# MCU_ECC_AGGR1_ECC_AGGR register map
Vendor: Texas Instruments
Peripheral module from a debugger description file (folder am65x).
Registers are 32-bit, access not given, reset 0x0 unless marked. A register's access mark holds for its fields unless they carry their own. Offsets are as the file gives them; lines under a group give offsets from that group; [hi:lo] are bit positions; {n}, {i} and the like mark numbered series; 'fields as' and 'values as' point back to an identical list; <NAME> marks a mode.

## MCU_ECC_AGGR1_ECC_AGGR (part 1 of 2)
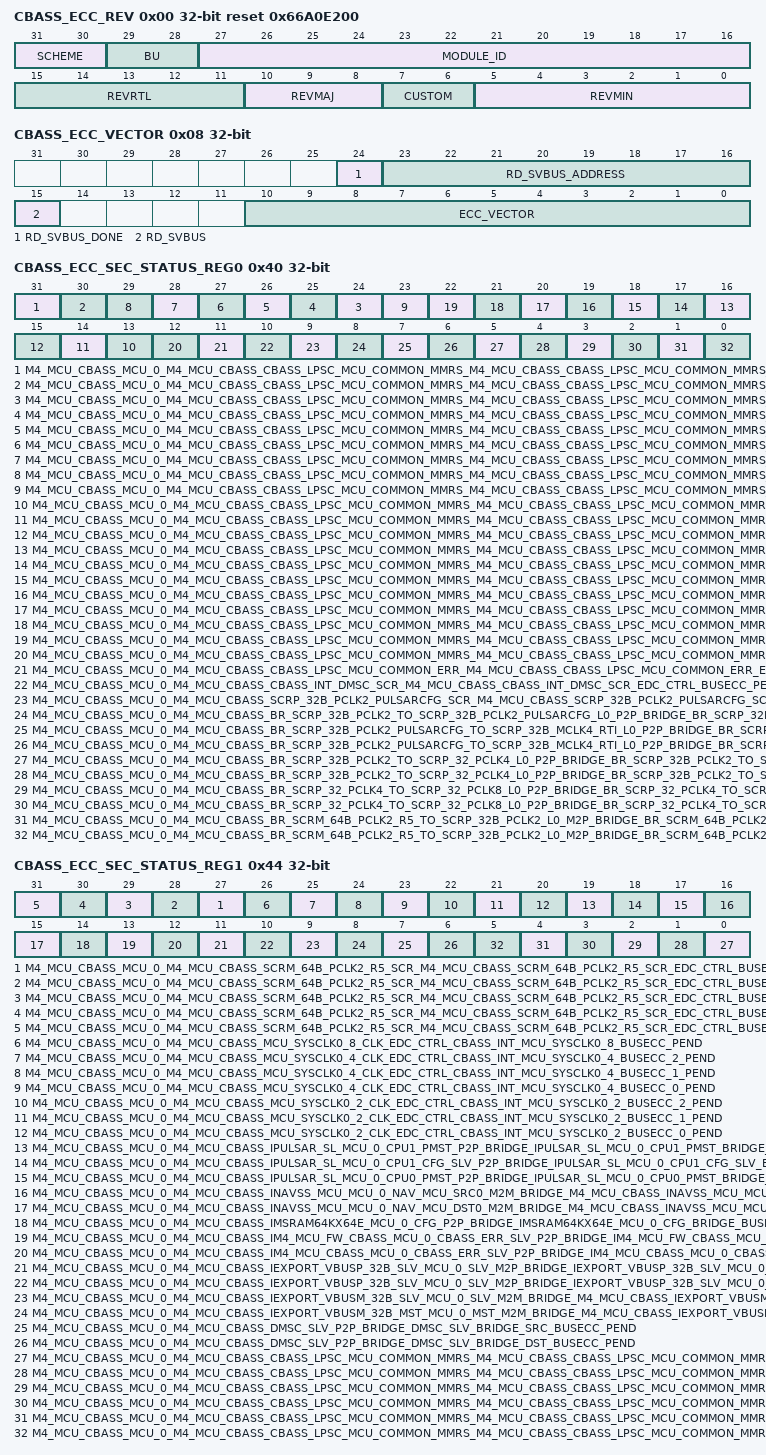
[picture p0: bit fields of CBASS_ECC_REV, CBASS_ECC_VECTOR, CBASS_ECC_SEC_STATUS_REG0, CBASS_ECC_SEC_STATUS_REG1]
0x00 CBASS_ECC_REV ro reset 0x66A0E200 — Return to the . Revision parameters
  [31:30] SCHEME
  [29:28] BU
  [27:16] MODULE_ID
  [15:11] REVRTL — RTL version
  [10:8] REVMAJ — Major version
  [7:6] CUSTOM — Custom version
  [5:0] REVMIN — Minor version
0x08 CBASS_ECC_VECTOR — Return to the . ECC Vector Register
  [24] RD_SVBUS_DONE — Status to indicate if read on serial VBUS is complete, write of any value will clear this bit. (access RW1C)
  [23:16] RD_SVBUS_ADDRESS rw — Read address
  [15] RD_SVBUS — Write 1 to trigger a read on the serial VBUS (access RW1S)
  [10:0] ECC_VECTOR rw — Value written to select the corresponding ECC RAM for control or status
0x0C CBASS_ECC_STAT ro reset 0x57 — Return to the . Misc Status
  [10:0] NUM_RAMS — Indicates the number of RAMS serviced by the ECC aggregator
0x3C CBASS_ECC_SEC_EOI_REG — Return to the . EOI Register
  [0] EOI_WR — EOI Register (access RW1S)
0x40 CBASS_ECC_SEC_STATUS_REG0 — Return to the . Interrupt Status Register 0
  [31] M4_MCU_CBASS_MCU_0_M4_MCU_CBASS_CBASS_LPSC_MCU_COMMON_MMRS_M4_MCU_CBASS_CBASS_LPSC_MCU_COMMON_MMRS_EDC_CTRL_BUSECC_3_PEND — Interrupt Pending Status for m4_mcu_cbass_mcu_0_m4_mcu_cbass_cbass_LPSC_mcu_common_mmrs_m4_mcu_cbass_cbass_LPSC_mcu_common_mmrs_edc_ctrl_busecc_3__pend (access RW1S)
  [30] M4_MCU_CBASS_MCU_0_M4_MCU_CBASS_CBASS_LPSC_MCU_COMMON_MMRS_M4_MCU_CBASS_CBASS_LPSC_MCU_COMMON_MMRS_EDC_CTRL_BUSECC_2_PEND — Interrupt Pending Status for m4_mcu_cbass_mcu_0_m4_mcu_cbass_cbass_LPSC_mcu_common_mmrs_m4_mcu_cbass_cbass_LPSC_mcu_common_mmrs_edc_ctrl_busecc_2__pend (access RW1S)
  [n+4] M4_MCU_CBASS_MCU_0_M4_MCU_CBASS_CBASS_LPSC_MCU_COMMON_MMRS_M4_MCU_CBASS_CBASS_LPSC_MCU_COMMON_MMRS_EDC_CTRL_BUSECC_{n}_PEND (n=20..25) — Interrupt Pending Status for m4_mcu_cbass_mcu_0_m4_mcu_cbass_cbass_LPSC_mcu_common_mmrs_m4_mcu_cbass_cbass_LPSC_mcu_common_mmrs_edc_ctrl_busecc_{n}__pend (access RW1S)
  [23] M4_MCU_CBASS_MCU_0_M4_MCU_CBASS_CBASS_LPSC_MCU_COMMON_MMRS_M4_MCU_CBASS_CBASS_LPSC_MCU_COMMON_MMRS_EDC_CTRL_BUSECC_1_PEND — Interrupt Pending Status for m4_mcu_cbass_mcu_0_m4_mcu_cbass_cbass_LPSC_mcu_common_mmrs_m4_mcu_cbass_cbass_LPSC_mcu_common_mmrs_edc_ctrl_busecc_1__pend (access RW1S)
  [n+3] M4_MCU_CBASS_MCU_0_M4_MCU_CBASS_CBASS_LPSC_MCU_COMMON_MMRS_M4_MCU_CBASS_CBASS_LPSC_MCU_COMMON_MMRS_EDC_CTRL_BUSECC_{n}_PEND (n=10..19) — Interrupt Pending Status for m4_mcu_cbass_mcu_0_m4_mcu_cbass_cbass_LPSC_mcu_common_mmrs_m4_mcu_cbass_cbass_LPSC_mcu_common_mmrs_edc_ctrl_busecc_{n}__pend (access RW1S)
  [12] M4_MCU_CBASS_MCU_0_M4_MCU_CBASS_CBASS_LPSC_MCU_COMMON_MMRS_M4_MCU_CBASS_CBASS_LPSC_MCU_COMMON_MMRS_EDC_CTRL_BUSECC_0_PEND — Interrupt Pending Status for m4_mcu_cbass_mcu_0_m4_mcu_cbass_cbass_LPSC_mcu_common_mmrs_m4_mcu_cbass_cbass_LPSC_mcu_common_mmrs_edc_ctrl_busecc_0__pend (access RW1S)
  [11] M4_MCU_CBASS_MCU_0_M4_MCU_CBASS_CBASS_LPSC_MCU_COMMON_ERR_M4_MCU_CBASS_CBASS_LPSC_MCU_COMMON_ERR_EDC_CTRL_BUSECC_PEND — Interrupt Pending Status for m4_mcu_cbass_mcu_0_m4_mcu_cbass_cbass_LPSC_mcu_common_err_m4_mcu_cbass_cbass_LPSC_mcu_common_err_edc_ctrl_busecc__pend (access RW1S)
  [10] M4_MCU_CBASS_MCU_0_M4_MCU_CBASS_CBASS_INT_DMSC_SCR_M4_MCU_CBASS_CBASS_INT_DMSC_SCR_EDC_CTRL_BUSECC_PEND — Interrupt Pending Status for m4_mcu_cbass_mcu_0_m4_mcu_cbass_cbass_int_dmsc_scr_m4_mcu_cbass_cbass_int_dmsc_scr_edc_ctrl_busecc__pend (access RW1S)
  [9] M4_MCU_CBASS_MCU_0_M4_MCU_CBASS_SCRP_32B_PCLK2_PULSARCFG_SCR_M4_MCU_CBASS_SCRP_32B_PCLK2_PULSARCFG_SCR_EDC_CTRL_BUSECC_0_PEND — Interrupt Pending Status for m4_mcu_cbass_mcu_0_m4_mcu_cbass_SCRP_32b_PCLK2_Pulsarcfg_scr_m4_mcu_cbass_SCRP_32b_PCLK2_Pulsarcfg_scr_edc_ctrl_busecc_0__pend (access RW1S)
  [8] M4_MCU_CBASS_MCU_0_M4_MCU_CBASS_BR_SCRP_32B_PCLK2_TO_SCRP_32B_PCLK2_PULSARCFG_L0_P2P_BRIDGE_BR_SCRP_32B_PCLK2_TO_SCRP_32B_PCLK2_PULSARCFG_L0_BRIDGE_BUSECC_PEND — Interrupt Pending Status for m4_mcu_cbass_mcu_0_m4_mcu_cbass_br_SCRP_32b_PCLK2_to_SCRP_32b_PCLK2_Pulsarcfg_l0_p2p_bridge_br_SCRP_32b_PCLK2_to_SCRP_32b_PCLK2_Pulsarcfg_l0_bridge_busecc__pend (access RW1S)
  [7] M4_MCU_CBASS_MCU_0_M4_MCU_CBASS_BR_SCRP_32B_PCLK2_PULSARCFG_TO_SCRP_32B_MCLK4_RTI_L0_P2P_BRIDGE_BR_SCRP_32B_PCLK2_PULSARCFG_TO_SCRP_32B_MCLK4_RTI_L0_BRIDGE_SRC_BUSECC_PEND — Interrupt Pending Status for m4_mcu_cbass_mcu_0_m4_mcu_cbass_br_SCRP_32b_PCLK2_Pulsarcfg_to_SCRP_32b_MCLK4_rti_l0_p2p_bridge_br_SCRP_32b_PCLK2_Pulsarcfg_to_SCRP_32b_MCLK4_rti_l0_bridge_src_busecc__pend (access RW1S)
  [6] M4_MCU_CBASS_MCU_0_M4_MCU_CBASS_BR_SCRP_32B_PCLK2_PULSARCFG_TO_SCRP_32B_MCLK4_RTI_L0_P2P_BRIDGE_BR_SCRP_32B_PCLK2_PULSARCFG_TO_SCRP_32B_MCLK4_RTI_L0_BRIDGE_DST_BUSECC_PEND — Interrupt Pending Status for m4_mcu_cbass_mcu_0_m4_mcu_cbass_br_SCRP_32b_PCLK2_Pulsarcfg_to_SCRP_32b_MCLK4_rti_l0_p2p_bridge_br_SCRP_32b_PCLK2_Pulsarcfg_to_SCRP_32b_MCLK4_rti_l0_bridge_dst_busecc__pend (access RW1S)
  [5] M4_MCU_CBASS_MCU_0_M4_MCU_CBASS_BR_SCRP_32B_PCLK2_TO_SCRP_32_PCLK4_L0_P2P_BRIDGE_BR_SCRP_32B_PCLK2_TO_SCRP_32_PCLK4_L0_BRIDGE_SRC_BUSECC_PEND — Interrupt Pending Status for m4_mcu_cbass_mcu_0_m4_mcu_cbass_br_SCRP_32b_PCLK2_to_SCRP_32_PCLK4_l0_p2p_bridge_br_SCRP_32b_PCLK2_to_SCRP_32_PCLK4_l0_bridge_src_busecc__pend (access RW1S)
  [4] M4_MCU_CBASS_MCU_0_M4_MCU_CBASS_BR_SCRP_32B_PCLK2_TO_SCRP_32_PCLK4_L0_P2P_BRIDGE_BR_SCRP_32B_PCLK2_TO_SCRP_32_PCLK4_L0_BRIDGE_DST_BUSECC_PEND — Interrupt Pending Status for m4_mcu_cbass_mcu_0_m4_mcu_cbass_br_SCRP_32b_PCLK2_to_SCRP_32_PCLK4_l0_p2p_bridge_br_SCRP_32b_PCLK2_to_SCRP_32_PCLK4_l0_bridge_dst_busecc__pend (access RW1S)
  [3] M4_MCU_CBASS_MCU_0_M4_MCU_CBASS_BR_SCRP_32_PCLK4_TO_SCRP_32_PCLK8_L0_P2P_BRIDGE_BR_SCRP_32_PCLK4_TO_SCRP_32_PCLK8_L0_BRIDGE_SRC_BUSECC_PEND — Interrupt Pending Status for m4_mcu_cbass_mcu_0_m4_mcu_cbass_br_SCRP_32_PCLK4_to_SCRP_32_PCLK8_l0_p2p_bridge_br_SCRP_32_PCLK4_to_SCRP_32_PCLK8_l0_bridge_src_busecc__pend (access RW1S)
  [2] M4_MCU_CBASS_MCU_0_M4_MCU_CBASS_BR_SCRP_32_PCLK4_TO_SCRP_32_PCLK8_L0_P2P_BRIDGE_BR_SCRP_32_PCLK4_TO_SCRP_32_PCLK8_L0_BRIDGE_DST_BUSECC_PEND — Interrupt Pending Status for m4_mcu_cbass_mcu_0_m4_mcu_cbass_br_SCRP_32_PCLK4_to_SCRP_32_PCLK8_l0_p2p_bridge_br_SCRP_32_PCLK4_to_SCRP_32_PCLK8_l0_bridge_dst_busecc__pend (access RW1S)
  [1] M4_MCU_CBASS_MCU_0_M4_MCU_CBASS_BR_SCRM_64B_PCLK2_R5_TO_SCRP_32B_PCLK2_L0_M2P_BRIDGE_BR_SCRM_64B_PCLK2_R5_TO_SCRP_32B_PCLK2_L0_BRIDGE_SRC_BUSECC_PEND — Interrupt Pending Status for m4_mcu_cbass_mcu_0_m4_mcu_cbass_br_SCRM_64b_PCLK2_R5_to_SCRP_32b_PCLK2_l0_m2p_bridge_br_SCRM_64b_PCLK2_R5_to_SCRP_32b_PCLK2_l0_bridge_src_busecc__pend (access RW1S)
  [0] M4_MCU_CBASS_MCU_0_M4_MCU_CBASS_BR_SCRM_64B_PCLK2_R5_TO_SCRP_32B_PCLK2_L0_M2P_BRIDGE_BR_SCRM_64B_PCLK2_R5_TO_SCRP_32B_PCLK2_L0_BRIDGE_DST_BUSECC_PEND — Interrupt Pending Status for m4_mcu_cbass_mcu_0_m4_mcu_cbass_br_SCRM_64b_PCLK2_R5_to_SCRP_32b_PCLK2_l0_m2p_bridge_br_SCRM_64b_PCLK2_R5_to_SCRP_32b_PCLK2_l0_bridge_dst_busecc__pend (access RW1S)
0x44 CBASS_ECC_SEC_STATUS_REG1 — Return to the . Interrupt Status Register 1
  [n+27] M4_MCU_CBASS_MCU_0_M4_MCU_CBASS_SCRM_64B_PCLK2_R5_SCR_M4_MCU_CBASS_SCRM_64B_PCLK2_R5_SCR_EDC_CTRL_BUSECC_{n}_PEND (n=0..4) — Interrupt Pending Status for m4_mcu_cbass_mcu_0_m4_mcu_cbass_SCRM_64b_PCLK2_R5_scr_m4_mcu_cbass_SCRM_64b_PCLK2_R5_scr_edc_ctrl_busecc_{n}__pend (access RW1S)
  [26] M4_MCU_CBASS_MCU_0_M4_MCU_CBASS_MCU_SYSCLK0_8_CLK_EDC_CTRL_CBASS_INT_MCU_SYSCLK0_8_BUSECC_PEND — Interrupt Pending Status for m4_mcu_cbass_mcu_0_m4_mcu_cbass_mcu_sysclk0_8_clk_edc_ctrl_cbass_int_mcu_sysclk0_8_busecc__pend (access RW1S)
  [25] M4_MCU_CBASS_MCU_0_M4_MCU_CBASS_MCU_SYSCLK0_4_CLK_EDC_CTRL_CBASS_INT_MCU_SYSCLK0_4_BUSECC_2_PEND — Interrupt Pending Status for m4_mcu_cbass_mcu_0_m4_mcu_cbass_mcu_sysclk0_4_clk_edc_ctrl_cbass_int_mcu_sysclk0_4_busecc_2__pend (access RW1S)
  [24] M4_MCU_CBASS_MCU_0_M4_MCU_CBASS_MCU_SYSCLK0_4_CLK_EDC_CTRL_CBASS_INT_MCU_SYSCLK0_4_BUSECC_1_PEND — Interrupt Pending Status for m4_mcu_cbass_mcu_0_m4_mcu_cbass_mcu_sysclk0_4_clk_edc_ctrl_cbass_int_mcu_sysclk0_4_busecc_1__pend (access RW1S)
  [23] M4_MCU_CBASS_MCU_0_M4_MCU_CBASS_MCU_SYSCLK0_4_CLK_EDC_CTRL_CBASS_INT_MCU_SYSCLK0_4_BUSECC_0_PEND — Interrupt Pending Status for m4_mcu_cbass_mcu_0_m4_mcu_cbass_mcu_sysclk0_4_clk_edc_ctrl_cbass_int_mcu_sysclk0_4_busecc_0__pend (access RW1S)
  [22] M4_MCU_CBASS_MCU_0_M4_MCU_CBASS_MCU_SYSCLK0_2_CLK_EDC_CTRL_CBASS_INT_MCU_SYSCLK0_2_BUSECC_2_PEND — Interrupt Pending Status for m4_mcu_cbass_mcu_0_m4_mcu_cbass_mcu_sysclk0_2_clk_edc_ctrl_cbass_int_mcu_sysclk0_2_busecc_2__pend (access RW1S)
  [21] M4_MCU_CBASS_MCU_0_M4_MCU_CBASS_MCU_SYSCLK0_2_CLK_EDC_CTRL_CBASS_INT_MCU_SYSCLK0_2_BUSECC_1_PEND — Interrupt Pending Status for m4_mcu_cbass_mcu_0_m4_mcu_cbass_mcu_sysclk0_2_clk_edc_ctrl_cbass_int_mcu_sysclk0_2_busecc_1__pend (access RW1S)
  [20] M4_MCU_CBASS_MCU_0_M4_MCU_CBASS_MCU_SYSCLK0_2_CLK_EDC_CTRL_CBASS_INT_MCU_SYSCLK0_2_BUSECC_0_PEND — Interrupt Pending Status for m4_mcu_cbass_mcu_0_m4_mcu_cbass_mcu_sysclk0_2_clk_edc_ctrl_cbass_int_mcu_sysclk0_2_busecc_0__pend (access RW1S)
  [19] M4_MCU_CBASS_MCU_0_M4_MCU_CBASS_IPULSAR_SL_MCU_0_CPU1_PMST_P2P_BRIDGE_IPULSAR_SL_MCU_0_CPU1_PMST_BRIDGE_BUSECC_PEND — Interrupt Pending Status for m4_mcu_cbass_mcu_0_m4_mcu_cbass_Ipulsar_sl_mcu_0_cpu1_pmst_p2p_bridge_Ipulsar_sl_mcu_0_cpu1_pmst_bridge_busecc__pend (access RW1S)
  [18] M4_MCU_CBASS_MCU_0_M4_MCU_CBASS_IPULSAR_SL_MCU_0_CPU1_CFG_SLV_P2P_BRIDGE_IPULSAR_SL_MCU_0_CPU1_CFG_SLV_BRIDGE_BUSECC_PEND — Interrupt Pending Status for m4_mcu_cbass_mcu_0_m4_mcu_cbass_Ipulsar_sl_mcu_0_cpu1_cfg_slv_p2p_bridge_Ipulsar_sl_mcu_0_cpu1_cfg_slv_bridge_busecc__pend (access RW1S)
  [17] M4_MCU_CBASS_MCU_0_M4_MCU_CBASS_IPULSAR_SL_MCU_0_CPU0_PMST_P2P_BRIDGE_IPULSAR_SL_MCU_0_CPU0_PMST_BRIDGE_BUSECC_PEND — Interrupt Pending Status for m4_mcu_cbass_mcu_0_m4_mcu_cbass_Ipulsar_sl_mcu_0_cpu0_pmst_p2p_bridge_Ipulsar_sl_mcu_0_cpu0_pmst_bridge_busecc__pend (access RW1S)
  [16] M4_MCU_CBASS_MCU_0_M4_MCU_CBASS_INAVSS_MCU_MCU_0_NAV_MCU_SRC0_M2M_BRIDGE_M4_MCU_CBASS_INAVSS_MCU_MCU_0_NAV_MCU_SRC0_M2M_BRIDGE_SRC_EDC_CTRL_BUSECC_PEND — Interrupt Pending Status for m4_mcu_cbass_mcu_0_m4_mcu_cbass_Inavss_mcu_mcu_0_nav_mcu_src0_m2m_bridge_m4_mcu_cbass_Inavss_mcu_mcu_0_nav_mcu_src0_m2m_bridge_src_edc_ctrl_busecc__pend (access RW1S)
  [15] M4_MCU_CBASS_MCU_0_M4_MCU_CBASS_INAVSS_MCU_MCU_0_NAV_MCU_DST0_M2M_BRIDGE_M4_MCU_CBASS_INAVSS_MCU_MCU_0_NAV_MCU_DST0_M2M_BRIDGE_SRC_EDC_CTRL_BUSECC_PEND — Interrupt Pending Status for m4_mcu_cbass_mcu_0_m4_mcu_cbass_Inavss_mcu_mcu_0_nav_mcu_dst0_m2m_bridge_m4_mcu_cbass_Inavss_mcu_mcu_0_nav_mcu_dst0_m2m_bridge_src_edc_ctrl_busecc__pend (access RW1S)
  [14] M4_MCU_CBASS_MCU_0_M4_MCU_CBASS_IMSRAM64KX64E_MCU_0_CFG_P2P_BRIDGE_IMSRAM64KX64E_MCU_0_CFG_BRIDGE_BUSECC_PEND — Interrupt Pending Status for m4_mcu_cbass_mcu_0_m4_mcu_cbass_Imsram64kx64e_mcu_0_cfg_p2p_bridge_Imsram64kx64e_mcu_0_cfg_bridge_busecc__pend (access RW1S)
  [13] M4_MCU_CBASS_MCU_0_M4_MCU_CBASS_IM4_MCU_FW_CBASS_MCU_0_CBASS_ERR_SLV_P2P_BRIDGE_IM4_MCU_FW_CBASS_MCU_0_CBASS_ERR_SLV_BRIDGE_BUSECC_PEND — Interrupt Pending Status for m4_mcu_cbass_mcu_0_m4_mcu_cbass_Im4_mcu_fw_cbass_mcu_0_cbass_err_slv_p2p_bridge_Im4_mcu_fw_cbass_mcu_0_cbass_err_slv_bridge_busecc__pend (access RW1S)
  [12] M4_MCU_CBASS_MCU_0_M4_MCU_CBASS_IM4_MCU_CBASS_MCU_0_CBASS_ERR_SLV_P2P_BRIDGE_IM4_MCU_CBASS_MCU_0_CBASS_ERR_SLV_BRIDGE_BUSECC_PEND — Interrupt Pending Status for m4_mcu_cbass_mcu_0_m4_mcu_cbass_Im4_mcu_cbass_mcu_0_cbass_err_slv_p2p_bridge_Im4_mcu_cbass_mcu_0_cbass_err_slv_bridge_busecc__pend (access RW1S)
  [11] M4_MCU_CBASS_MCU_0_M4_MCU_CBASS_IEXPORT_VBUSP_32B_SLV_MCU_0_SLV_M2P_BRIDGE_IEXPORT_VBUSP_32B_SLV_MCU_0_SLV_BRIDGE_SRC_BUSECC_PEND — Interrupt Pending Status for m4_mcu_cbass_mcu_0_m4_mcu_cbass_Iexport_vbusp_32b_slv_mcu_0_slv_m2p_bridge_Iexport_vbusp_32b_slv_mcu_0_slv_bridge_src_busecc__pend (access RW1S)
  [10] M4_MCU_CBASS_MCU_0_M4_MCU_CBASS_IEXPORT_VBUSP_32B_SLV_MCU_0_SLV_M2P_BRIDGE_IEXPORT_VBUSP_32B_SLV_MCU_0_SLV_BRIDGE_DST_BUSECC_PEND — Interrupt Pending Status for m4_mcu_cbass_mcu_0_m4_mcu_cbass_Iexport_vbusp_32b_slv_mcu_0_slv_m2p_bridge_Iexport_vbusp_32b_slv_mcu_0_slv_bridge_dst_busecc__pend (access RW1S)
  [9] M4_MCU_CBASS_MCU_0_M4_MCU_CBASS_IEXPORT_VBUSM_32B_SLV_MCU_0_SLV_M2M_BRIDGE_M4_MCU_CBASS_IEXPORT_VBUSM_32B_SLV_MCU_0_SLV_M2M_BRIDGE_SRC_EDC_CTRL_BUSECC_PEND — Interrupt Pending Status for m4_mcu_cbass_mcu_0_m4_mcu_cbass_Iexport_vbusm_32b_slv_mcu_0_slv_m2m_bridge_m4_mcu_cbass_Iexport_vbusm_32b_slv_mcu_0_slv_m2m_bridge_src_edc_ctrl_busecc__pend (access RW1S)
  [8] M4_MCU_CBASS_MCU_0_M4_MCU_CBASS_IEXPORT_VBUSM_32B_MST_MCU_0_MST_M2M_BRIDGE_M4_MCU_CBASS_IEXPORT_VBUSM_32B_MST_MCU_0_MST_M2M_BRIDGE_SRC_EDC_CTRL_BUSECC_PEND — Interrupt Pending Status for m4_mcu_cbass_mcu_0_m4_mcu_cbass_Iexport_vbusm_32b_mst_mcu_0_mst_m2m_bridge_m4_mcu_cbass_Iexport_vbusm_32b_mst_mcu_0_mst_m2m_bridge_src_edc_ctrl_busecc__pend (access RW1S)
  [7] M4_MCU_CBASS_MCU_0_M4_MCU_CBASS_DMSC_SLV_P2P_BRIDGE_DMSC_SLV_BRIDGE_SRC_BUSECC_PEND — Interrupt Pending Status for m4_mcu_cbass_mcu_0_m4_mcu_cbass_dmsc_slv_p2p_bridge_dmsc_slv_bridge_src_busecc__pend (access RW1S)
  [6] M4_MCU_CBASS_MCU_0_M4_MCU_CBASS_DMSC_SLV_P2P_BRIDGE_DMSC_SLV_BRIDGE_DST_BUSECC_PEND — Interrupt Pending Status for m4_mcu_cbass_mcu_0_m4_mcu_cbass_dmsc_slv_p2p_bridge_dmsc_slv_bridge_dst_busecc__pend (access RW1S)
  [n-4] M4_MCU_CBASS_MCU_0_M4_MCU_CBASS_CBASS_LPSC_MCU_COMMON_MMRS_M4_MCU_CBASS_CBASS_LPSC_MCU_COMMON_MMRS_EDC_CTRL_BUSECC_{n}_PEND (n=4..9) — Interrupt Pending Status for m4_mcu_cbass_mcu_0_m4_mcu_cbass_cbass_LPSC_mcu_common_mmrs_m4_mcu_cbass_cbass_LPSC_mcu_common_mmrs_edc_ctrl_busecc_{n}__pend (access RW1S)
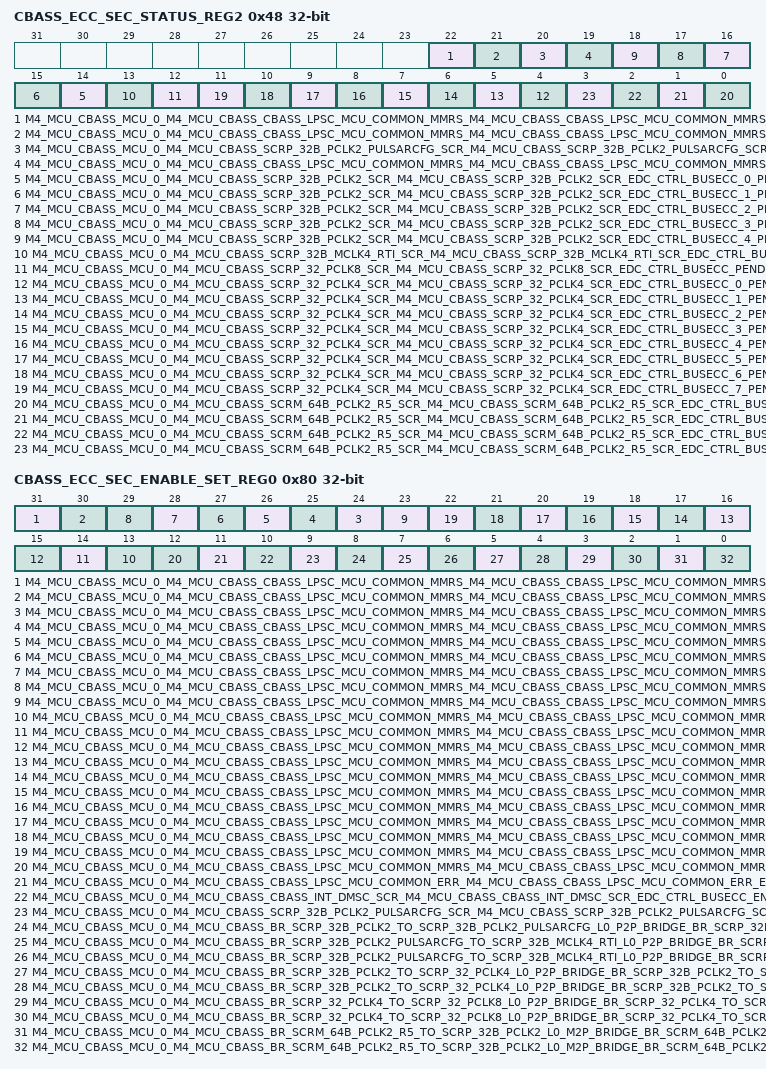
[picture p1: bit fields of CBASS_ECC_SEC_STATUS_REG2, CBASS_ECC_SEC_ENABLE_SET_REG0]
0x48 CBASS_ECC_SEC_STATUS_REG2 — Return to the . Interrupt Status Register 2
  [22] M4_MCU_CBASS_MCU_0_M4_MCU_CBASS_CBASS_LPSC_MCU_COMMON_MMRS_M4_MCU_CBASS_CBASS_LPSC_MCU_COMMON_MMRS_EDC_CTRL_BUSECC_28_PEND — Interrupt Pending Status for m4_mcu_cbass_mcu_0_m4_mcu_cbass_cbass_LPSC_mcu_common_mmrs_m4_mcu_cbass_cbass_LPSC_mcu_common_mmrs_edc_ctrl_busecc_28__pend (access RW1S)
  [21] M4_MCU_CBASS_MCU_0_M4_MCU_CBASS_CBASS_LPSC_MCU_COMMON_MMRS_M4_MCU_CBASS_CBASS_LPSC_MCU_COMMON_MMRS_EDC_CTRL_BUSECC_27_PEND — Interrupt Pending Status for m4_mcu_cbass_mcu_0_m4_mcu_cbass_cbass_LPSC_mcu_common_mmrs_m4_mcu_cbass_cbass_LPSC_mcu_common_mmrs_edc_ctrl_busecc_27__pend (access RW1S)
  [20] M4_MCU_CBASS_MCU_0_M4_MCU_CBASS_SCRP_32B_PCLK2_PULSARCFG_SCR_M4_MCU_CBASS_SCRP_32B_PCLK2_PULSARCFG_SCR_EDC_CTRL_BUSECC_1_PEND — Interrupt Pending Status for m4_mcu_cbass_mcu_0_m4_mcu_cbass_SCRP_32b_PCLK2_Pulsarcfg_scr_m4_mcu_cbass_SCRP_32b_PCLK2_Pulsarcfg_scr_edc_ctrl_busecc_1__pend (access RW1S)
  [19] M4_MCU_CBASS_MCU_0_M4_MCU_CBASS_CBASS_LPSC_MCU_COMMON_MMRS_M4_MCU_CBASS_CBASS_LPSC_MCU_COMMON_MMRS_EDC_CTRL_BUSECC_26_PEND — Interrupt Pending Status for m4_mcu_cbass_mcu_0_m4_mcu_cbass_cbass_LPSC_mcu_common_mmrs_m4_mcu_cbass_cbass_LPSC_mcu_common_mmrs_edc_ctrl_busecc_26__pend (access RW1S)
  [n+14] M4_MCU_CBASS_MCU_0_M4_MCU_CBASS_SCRP_32B_PCLK2_SCR_M4_MCU_CBASS_SCRP_32B_PCLK2_SCR_EDC_CTRL_BUSECC_{n}_PEND (n=0..4) — Interrupt Pending Status for m4_mcu_cbass_mcu_0_m4_mcu_cbass_SCRP_32b_PCLK2_scr_m4_mcu_cbass_SCRP_32b_PCLK2_scr_edc_ctrl_busecc_{n}__pend (access RW1S)
  [13] M4_MCU_CBASS_MCU_0_M4_MCU_CBASS_SCRP_32B_MCLK4_RTI_SCR_M4_MCU_CBASS_SCRP_32B_MCLK4_RTI_SCR_EDC_CTRL_BUSECC_PEND — Interrupt Pending Status for m4_mcu_cbass_mcu_0_m4_mcu_cbass_SCRP_32b_MCLK4_rti_scr_m4_mcu_cbass_SCRP_32b_MCLK4_rti_scr_edc_ctrl_busecc__pend (access RW1S)
  [12] M4_MCU_CBASS_MCU_0_M4_MCU_CBASS_SCRP_32_PCLK8_SCR_M4_MCU_CBASS_SCRP_32_PCLK8_SCR_EDC_CTRL_BUSECC_PEND — Interrupt Pending Status for m4_mcu_cbass_mcu_0_m4_mcu_cbass_SCRP_32_PCLK8_scr_m4_mcu_cbass_SCRP_32_PCLK8_scr_edc_ctrl_busecc__pend (access RW1S)
  [n+4] M4_MCU_CBASS_MCU_0_M4_MCU_CBASS_SCRP_32_PCLK4_SCR_M4_MCU_CBASS_SCRP_32_PCLK4_SCR_EDC_CTRL_BUSECC_{n}_PEND (n=0..7) — Interrupt Pending Status for m4_mcu_cbass_mcu_0_m4_mcu_cbass_SCRP_32_PCLK4_scr_m4_mcu_cbass_SCRP_32_PCLK4_scr_edc_ctrl_busecc_{n}__pend (access RW1S)
  [n-5] M4_MCU_CBASS_MCU_0_M4_MCU_CBASS_SCRM_64B_PCLK2_R5_SCR_M4_MCU_CBASS_SCRM_64B_PCLK2_R5_SCR_EDC_CTRL_BUSECC_{n}_PEND (n=5..8) — Interrupt Pending Status for m4_mcu_cbass_mcu_0_m4_mcu_cbass_SCRM_64b_PCLK2_R5_scr_m4_mcu_cbass_SCRM_64b_PCLK2_R5_scr_edc_ctrl_busecc_{n}__pend (access RW1S)
0x80 CBASS_ECC_SEC_ENABLE_SET_REG0 — Return to the . Interrupt Enable Set Register 0
  [31] M4_MCU_CBASS_MCU_0_M4_MCU_CBASS_CBASS_LPSC_MCU_COMMON_MMRS_M4_MCU_CBASS_CBASS_LPSC_MCU_COMMON_MMRS_EDC_CTRL_BUSECC_3_ENABLE_SET — Interrupt Enable Set Register for m4_mcu_cbass_mcu_0_m4_mcu_cbass_cbass_LPSC_mcu_common_mmrs_m4_mcu_cbass_cbass_LPSC_mcu_common_mmrs_edc_ctrl_busecc_3__pend (access RW1S)
  [30] M4_MCU_CBASS_MCU_0_M4_MCU_CBASS_CBASS_LPSC_MCU_COMMON_MMRS_M4_MCU_CBASS_CBASS_LPSC_MCU_COMMON_MMRS_EDC_CTRL_BUSECC_2_ENABLE_SET — Interrupt Enable Set Register for m4_mcu_cbass_mcu_0_m4_mcu_cbass_cbass_LPSC_mcu_common_mmrs_m4_mcu_cbass_cbass_LPSC_mcu_common_mmrs_edc_ctrl_busecc_2__pend (access RW1S)
  [n+4] M4_MCU_CBASS_MCU_0_M4_MCU_CBASS_CBASS_LPSC_MCU_COMMON_MMRS_M4_MCU_CBASS_CBASS_LPSC_MCU_COMMON_MMRS_EDC_CTRL_BUSECC_{n}_ENABLE_SET (n=20..25) — Interrupt Enable Set Register for m4_mcu_cbass_mcu_0_m4_mcu_cbass_cbass_LPSC_mcu_common_mmrs_m4_mcu_cbass_cbass_LPSC_mcu_common_mmrs_edc_ctrl_busecc_{n}__pend (access RW1S)
  [23] M4_MCU_CBASS_MCU_0_M4_MCU_CBASS_CBASS_LPSC_MCU_COMMON_MMRS_M4_MCU_CBASS_CBASS_LPSC_MCU_COMMON_MMRS_EDC_CTRL_BUSECC_1_ENABLE_SET — Interrupt Enable Set Register for m4_mcu_cbass_mcu_0_m4_mcu_cbass_cbass_LPSC_mcu_common_mmrs_m4_mcu_cbass_cbass_LPSC_mcu_common_mmrs_edc_ctrl_busecc_1__pend (access RW1S)
  [n+3] M4_MCU_CBASS_MCU_0_M4_MCU_CBASS_CBASS_LPSC_MCU_COMMON_MMRS_M4_MCU_CBASS_CBASS_LPSC_MCU_COMMON_MMRS_EDC_CTRL_BUSECC_{n}_ENABLE_SET (n=10..19) — Interrupt Enable Set Register for m4_mcu_cbass_mcu_0_m4_mcu_cbass_cbass_LPSC_mcu_common_mmrs_m4_mcu_cbass_cbass_LPSC_mcu_common_mmrs_edc_ctrl_busecc_{n}__pend (access RW1S)
  [12] M4_MCU_CBASS_MCU_0_M4_MCU_CBASS_CBASS_LPSC_MCU_COMMON_MMRS_M4_MCU_CBASS_CBASS_LPSC_MCU_COMMON_MMRS_EDC_CTRL_BUSECC_0_ENABLE_SET — Interrupt Enable Set Register for m4_mcu_cbass_mcu_0_m4_mcu_cbass_cbass_LPSC_mcu_common_mmrs_m4_mcu_cbass_cbass_LPSC_mcu_common_mmrs_edc_ctrl_busecc_0__pend (access RW1S)
  [11] M4_MCU_CBASS_MCU_0_M4_MCU_CBASS_CBASS_LPSC_MCU_COMMON_ERR_M4_MCU_CBASS_CBASS_LPSC_MCU_COMMON_ERR_EDC_CTRL_BUSECC_ENABLE_SET — Interrupt Enable Set Register for m4_mcu_cbass_mcu_0_m4_mcu_cbass_cbass_LPSC_mcu_common_err_m4_mcu_cbass_cbass_LPSC_mcu_common_err_edc_ctrl_busecc__pend (access RW1S)
  [10] M4_MCU_CBASS_MCU_0_M4_MCU_CBASS_CBASS_INT_DMSC_SCR_M4_MCU_CBASS_CBASS_INT_DMSC_SCR_EDC_CTRL_BUSECC_ENABLE_SET — Interrupt Enable Set Register for m4_mcu_cbass_mcu_0_m4_mcu_cbass_cbass_int_dmsc_scr_m4_mcu_cbass_cbass_int_dmsc_scr_edc_ctrl_busecc__pend (access RW1S)
  [9] M4_MCU_CBASS_MCU_0_M4_MCU_CBASS_SCRP_32B_PCLK2_PULSARCFG_SCR_M4_MCU_CBASS_SCRP_32B_PCLK2_PULSARCFG_SCR_EDC_CTRL_BUSECC_0_ENABLE_SET — Interrupt Enable Set Register for m4_mcu_cbass_mcu_0_m4_mcu_cbass_SCRP_32b_PCLK2_Pulsarcfg_scr_m4_mcu_cbass_SCRP_32b_PCLK2_Pulsarcfg_scr_edc_ctrl_busecc_0__pend (access RW1S)
  [8] M4_MCU_CBASS_MCU_0_M4_MCU_CBASS_BR_SCRP_32B_PCLK2_TO_SCRP_32B_PCLK2_PULSARCFG_L0_P2P_BRIDGE_BR_SCRP_32B_PCLK2_TO_SCRP_32B_PCLK2_PULSARCFG_L0_BRIDGE_BUSECC_ENABLE_SET — Interrupt Enable Set Register for m4_mcu_cbass_mcu_0_m4_mcu_cbass_br_SCRP_32b_PCLK2_to_SCRP_32b_PCLK2_Pulsarcfg_l0_p2p_bridge_br_SCRP_32b_PCLK2_to_SCRP_32b_PCLK2_Pulsarcfg_l0_bridge_busecc__pend (access RW1S)
  [7] M4_MCU_CBASS_MCU_0_M4_MCU_CBASS_BR_SCRP_32B_PCLK2_PULSARCFG_TO_SCRP_32B_MCLK4_RTI_L0_P2P_BRIDGE_BR_SCRP_32B_PCLK2_PULSARCFG_TO_SCRP_32B_MCLK4_RTI_L0_BRIDGE_SRC_BUSECC_ENABLE_SET — Interrupt Enable Set Register for m4_mcu_cbass_mcu_0_m4_mcu_cbass_br_SCRP_32b_PCLK2_Pulsarcfg_to_SCRP_32b_MCLK4_rti_l0_p2p_bridge_br_SCRP_32b_PCLK2_Pulsarcfg_to_SCRP_32b_MCLK4_rti_l0_bridge_src_busecc__pend (access RW1S)
  [6] M4_MCU_CBASS_MCU_0_M4_MCU_CBASS_BR_SCRP_32B_PCLK2_PULSARCFG_TO_SCRP_32B_MCLK4_RTI_L0_P2P_BRIDGE_BR_SCRP_32B_PCLK2_PULSARCFG_TO_SCRP_32B_MCLK4_RTI_L0_BRIDGE_DST_BUSECC_ENABLE_SET — Interrupt Enable Set Register for m4_mcu_cbass_mcu_0_m4_mcu_cbass_br_SCRP_32b_PCLK2_Pulsarcfg_to_SCRP_32b_MCLK4_rti_l0_p2p_bridge_br_SCRP_32b_PCLK2_Pulsarcfg_to_SCRP_32b_MCLK4_rti_l0_bridge_dst_busecc__pend (access RW1S)
  [5] M4_MCU_CBASS_MCU_0_M4_MCU_CBASS_BR_SCRP_32B_PCLK2_TO_SCRP_32_PCLK4_L0_P2P_BRIDGE_BR_SCRP_32B_PCLK2_TO_SCRP_32_PCLK4_L0_BRIDGE_SRC_BUSECC_ENABLE_SET — Interrupt Enable Set Register for m4_mcu_cbass_mcu_0_m4_mcu_cbass_br_SCRP_32b_PCLK2_to_SCRP_32_PCLK4_l0_p2p_bridge_br_SCRP_32b_PCLK2_to_SCRP_32_PCLK4_l0_bridge_src_busecc__pend (access RW1S)
  [4] M4_MCU_CBASS_MCU_0_M4_MCU_CBASS_BR_SCRP_32B_PCLK2_TO_SCRP_32_PCLK4_L0_P2P_BRIDGE_BR_SCRP_32B_PCLK2_TO_SCRP_32_PCLK4_L0_BRIDGE_DST_BUSECC_ENABLE_SET — Interrupt Enable Set Register for m4_mcu_cbass_mcu_0_m4_mcu_cbass_br_SCRP_32b_PCLK2_to_SCRP_32_PCLK4_l0_p2p_bridge_br_SCRP_32b_PCLK2_to_SCRP_32_PCLK4_l0_bridge_dst_busecc__pend (access RW1S)
  [3] M4_MCU_CBASS_MCU_0_M4_MCU_CBASS_BR_SCRP_32_PCLK4_TO_SCRP_32_PCLK8_L0_P2P_BRIDGE_BR_SCRP_32_PCLK4_TO_SCRP_32_PCLK8_L0_BRIDGE_SRC_BUSECC_ENABLE_SET — Interrupt Enable Set Register for m4_mcu_cbass_mcu_0_m4_mcu_cbass_br_SCRP_32_PCLK4_to_SCRP_32_PCLK8_l0_p2p_bridge_br_SCRP_32_PCLK4_to_SCRP_32_PCLK8_l0_bridge_src_busecc__pend (access RW1S)
  [2] M4_MCU_CBASS_MCU_0_M4_MCU_CBASS_BR_SCRP_32_PCLK4_TO_SCRP_32_PCLK8_L0_P2P_BRIDGE_BR_SCRP_32_PCLK4_TO_SCRP_32_PCLK8_L0_BRIDGE_DST_BUSECC_ENABLE_SET — Interrupt Enable Set Register for m4_mcu_cbass_mcu_0_m4_mcu_cbass_br_SCRP_32_PCLK4_to_SCRP_32_PCLK8_l0_p2p_bridge_br_SCRP_32_PCLK4_to_SCRP_32_PCLK8_l0_bridge_dst_busecc__pend (access RW1S)
  [1] M4_MCU_CBASS_MCU_0_M4_MCU_CBASS_BR_SCRM_64B_PCLK2_R5_TO_SCRP_32B_PCLK2_L0_M2P_BRIDGE_BR_SCRM_64B_PCLK2_R5_TO_SCRP_32B_PCLK2_L0_BRIDGE_SRC_BUSECC_ENABLE_SET — Interrupt Enable Set Register for m4_mcu_cbass_mcu_0_m4_mcu_cbass_br_SCRM_64b_PCLK2_R5_to_SCRP_32b_PCLK2_l0_m2p_bridge_br_SCRM_64b_PCLK2_R5_to_SCRP_32b_PCLK2_l0_bridge_src_busecc__pend (access RW1S)
  [0] M4_MCU_CBASS_MCU_0_M4_MCU_CBASS_BR_SCRM_64B_PCLK2_R5_TO_SCRP_32B_PCLK2_L0_M2P_BRIDGE_BR_SCRM_64B_PCLK2_R5_TO_SCRP_32B_PCLK2_L0_BRIDGE_DST_BUSECC_ENABLE_SET — Interrupt Enable Set Register for m4_mcu_cbass_mcu_0_m4_mcu_cbass_br_SCRM_64b_PCLK2_R5_to_SCRP_32b_PCLK2_l0_m2p_bridge_br_SCRM_64b_PCLK2_R5_to_SCRP_32b_PCLK2_l0_bridge_dst_busecc__pend (access RW1S)
